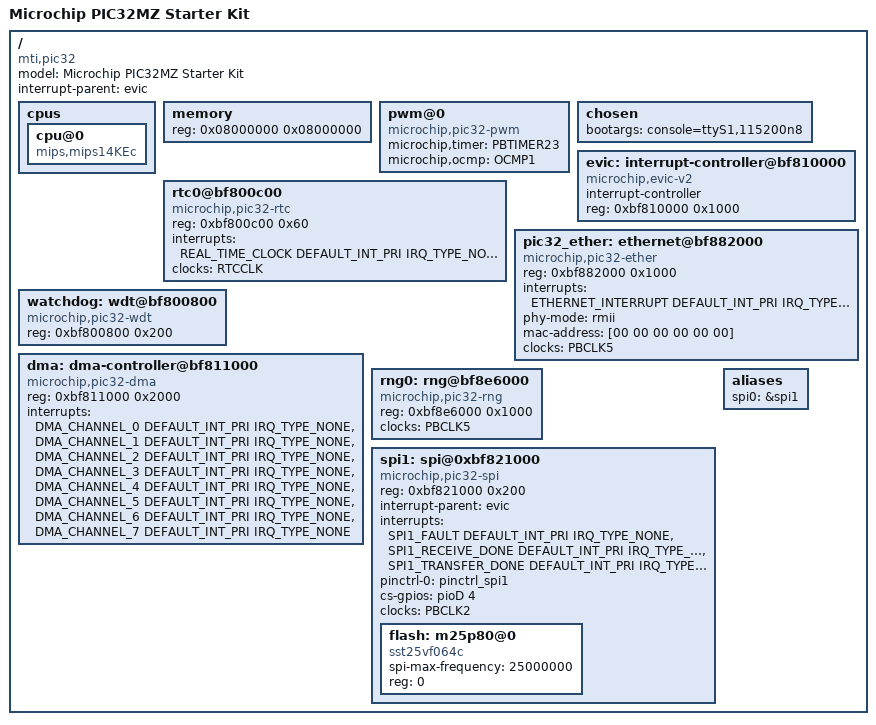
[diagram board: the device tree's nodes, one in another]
/dts-v1/;
#include <dt-bindings/interrupt-controller/microchip,pic32mz-evic.h>

#include "pic32mz-clk.dtsi"
#include "pic32mz-timer.dtsi"
#include "pic32mz-oc.dtsi"
#include "pic32mz-pinctrl.dtsi"
#include "pic32mz-uart.dtsi"
#include "pic32mz-i2c.dtsi"
#include "pic32mz-i2s.dtsi"
#include "eplatform-sdhc.dtsi"

/ {
	#address-cells = <1>;
	#size-cells = <1>;
	compatible = "mti,pic32";
	model = "Microchip PIC32MZ Starter Kit";
	interrupt-parent = <&evic>;

	cpus {
		cpu@0 {
			compatible = "mips,mips14KEc";
		};
	};

        memory {
                device_type = "memory";
                reg = <0x08000000 0x08000000>;
        };

	pwm@0 {
		compatible = "microchip,pic32-pwm";
		microchip,timer = <&PBTIMER23>; /* pbtimer phandle */
		microchip,ocmp = <&OCMP1>; /* ocmp phandle */
		//status = "disabled";
#if 0
		pinctrl-names = "default";
		pinctrl-0 = <&pinctrl_pwm0>;
#endif
	};

	chosen {
		bootargs = "console=ttyS1,115200n8";
	};

	evic: interrupt-controller@bf810000 {
		compatible = "microchip,evic-v2";
		interrupt-controller;
		#interrupt-cells = <3>;
		reg = <0xbf810000 0x1000>;
		device_type="evic-v2";
	};

	rtc0@bf800c00 {
		compatible = "microchip,pic32-rtc";
		reg = <0xbf800c00 0x60>;
		interrupts = <REAL_TIME_CLOCK DEFAULT_INT_PRI IRQ_TYPE_NONE>;
		clocks = <&RTCCLK>;
	};

	pic32_ether: ethernet@bf882000 {
		compatible = "microchip,pic32-ether";
		reg = <0xbf882000 0x1000>;
		interrupts = <ETHERNET_INTERRUPT DEFAULT_INT_PRI IRQ_TYPE_NONE>;
		phy-mode = "rmii";
		mac-address = [00 00 00 00 00 00];
		clock-names = "eth_clk";
		clocks = <&PBCLK5>;
	};

	watchdog: wdt@bf800800 {
		compatible = "microchip,pic32-wdt";
		reg = <0xbf800800 0x200>;
	};

	dma: dma-controller@bf811000 {
		compatible = "microchip,pic32-dma";
		reg = <0xbf811000 0x2000>;
		interrupts = <DMA_CHANNEL_0 DEFAULT_INT_PRI IRQ_TYPE_NONE>,
			<DMA_CHANNEL_1 DEFAULT_INT_PRI IRQ_TYPE_NONE>,
			<DMA_CHANNEL_2 DEFAULT_INT_PRI IRQ_TYPE_NONE>,
			<DMA_CHANNEL_3 DEFAULT_INT_PRI IRQ_TYPE_NONE>,
			<DMA_CHANNEL_4 DEFAULT_INT_PRI IRQ_TYPE_NONE>,
			<DMA_CHANNEL_5 DEFAULT_INT_PRI IRQ_TYPE_NONE>,
			<DMA_CHANNEL_6 DEFAULT_INT_PRI IRQ_TYPE_NONE>,
			<DMA_CHANNEL_7 DEFAULT_INT_PRI IRQ_TYPE_NONE>;
		#dma-cells = <1>;
	};

	rng0: rng@bf8e6000 {
		compatible = "microchip,pic32-rng";
		reg = <0xbf8e6000 0x1000>;
		clocks = <&PBCLK5>;
	};

	spi1:spi@0xbf821000 {
		#address-cells = <1>;
		#size-cells = <0>;
		compatible = "microchip,pic32-spi";
		reg = <0xbf821000 0x200>;
		interrupt-parent = <&evic>;
		interrupts = <SPI1_FAULT DEFAULT_INT_PRI IRQ_TYPE_NONE>,
			     <SPI1_RECEIVE_DONE DEFAULT_INT_PRI IRQ_TYPE_NONE>,
			     <SPI1_TRANSFER_DONE DEFAULT_INT_PRI IRQ_TYPE_NONE>;
		pinctrl-names = "default";
		pinctrl-0 = <&pinctrl_spi1>;
		cs-gpios = <&pioD 4 0>; /* #gpio-cells = <2>, first cell is pin# and second one unused */
		clocks = <&PBCLK2>;
		flash: m25p80@0 {
			#address-cells = <1>;
			#size-cells = <0>;
			compatible = "sst25vf064c","m25p80";
			spi-max-frequency = <25000000>;
			reg = <0>;
		};
	};

	aliases {
		spi0 = &spi1;
	};
};
